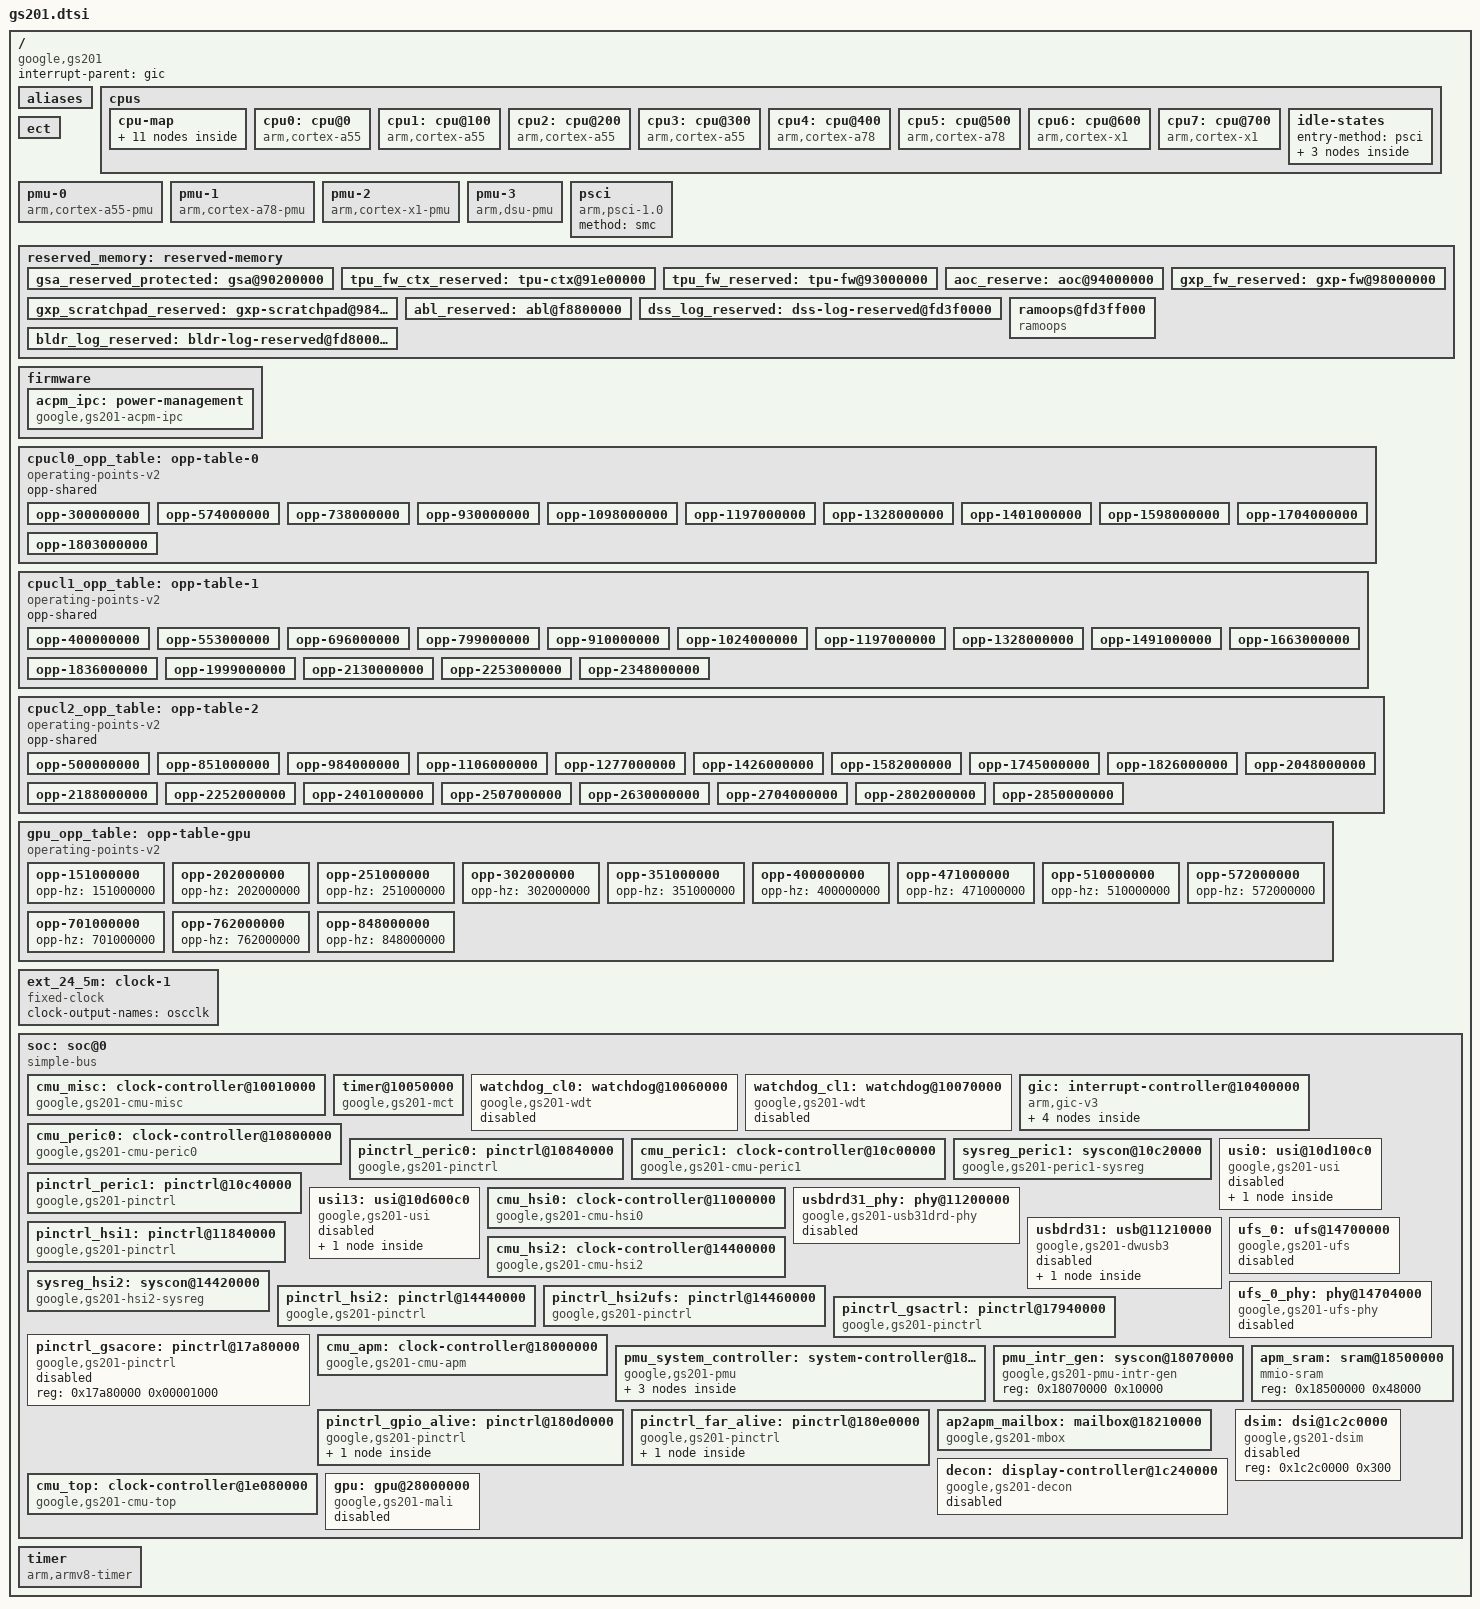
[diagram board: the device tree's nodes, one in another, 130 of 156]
// SPDX-License-Identifier: GPL-2.0-only
/*
 * GS201 SoC
 *
 * Copyright 2021-2023 Google LLC
 * Copyright 2023 Linaro Ltd - <peter.griffin@linaro.org>
 */

#include <dt-bindings/clock/google,gs201-acpm.h>
#include <dt-bindings/clock/google,gs201.h>
#include <dt-bindings/interrupt-controller/arm-gic.h>

/ {
	compatible = "google,gs201";
	#address-cells = <2>;
	#size-cells = <1>;

	interrupt-parent = <&gic>;

	aliases {
		pinctrl0 = &pinctrl_gpio_alive;
		pinctrl1 = &pinctrl_far_alive;
		pinctrl2 = &pinctrl_gsacore;
		pinctrl3 = &pinctrl_gsactrl;
		pinctrl4 = &pinctrl_peric0;
		pinctrl5 = &pinctrl_peric1;
		pinctrl6 = &pinctrl_hsi1;
		pinctrl7 = &pinctrl_hsi2;
		pinctrl8 = &pinctrl_hsi2ufs;
	};

	cpus {
		#address-cells = <1>;
		#size-cells = <0>;

		cpu-map {
			cluster0 {
				core0 {
					cpu = <&cpu0>;
				};

				core1 {
					cpu = <&cpu1>;
				};

				core2 {
					cpu = <&cpu2>;
				};

				core3 {
					cpu = <&cpu3>;
				};
			};

			cluster1 {
				core0 {
					cpu = <&cpu4>;
				};

				core1 {
					cpu = <&cpu5>;
				};
			};

			cluster2 {
				core0 {
					cpu = <&cpu6>;
				};

				core1 {
					cpu = <&cpu7>;
				};
			};
		};

		cpu0: cpu@0 {
			device_type = "cpu";
			compatible = "arm,cortex-a55";
			reg = <0x0000>;
			clocks = <&acpm_ipc GS201_CLK_ACPM_DVFS_CPUCL0>;
			enable-method = "psci";
			cpu-idle-states = <&ananke_cpu_sleep>;
			capacity-dmips-mhz = <250>;
			operating-points-v2 = <&cpucl0_opp_table>;
		};

		cpu1: cpu@100 {
			device_type = "cpu";
			compatible = "arm,cortex-a55";
			reg = <0x0100>;
			clocks = <&acpm_ipc GS201_CLK_ACPM_DVFS_CPUCL0>;
			enable-method = "psci";
			cpu-idle-states = <&ananke_cpu_sleep>;
			capacity-dmips-mhz = <250>;
			operating-points-v2 = <&cpucl0_opp_table>;
		};

		cpu2: cpu@200 {
			device_type = "cpu";
			compatible = "arm,cortex-a55";
			reg = <0x0200>;
			clocks = <&acpm_ipc GS201_CLK_ACPM_DVFS_CPUCL0>;
			enable-method = "psci";
			cpu-idle-states = <&ananke_cpu_sleep>;
			capacity-dmips-mhz = <250>;
			operating-points-v2 = <&cpucl0_opp_table>;
		};

		cpu3: cpu@300 {
			device_type = "cpu";
			compatible = "arm,cortex-a55";
			reg = <0x0300>;
			clocks = <&acpm_ipc GS201_CLK_ACPM_DVFS_CPUCL0>;
			enable-method = "psci";
			cpu-idle-states = <&ananke_cpu_sleep>;
			capacity-dmips-mhz = <250>;
			operating-points-v2 = <&cpucl0_opp_table>;
		};

		cpu4: cpu@400 {
			device_type = "cpu";
			compatible = "arm,cortex-a78";
			reg = <0x0400>;
			clocks = <&acpm_ipc GS201_CLK_ACPM_DVFS_CPUCL1>;
			enable-method = "psci";
			cpu-idle-states = <&hercules_cpu_sleep>;
			capacity-dmips-mhz = <927>;
			operating-points-v2 = <&cpucl1_opp_table>;
		};

		cpu5: cpu@500 {
			device_type = "cpu";
			compatible = "arm,cortex-a78";
			reg = <0x0500>;
			clocks = <&acpm_ipc GS201_CLK_ACPM_DVFS_CPUCL1>;
			enable-method = "psci";
			cpu-idle-states = <&hercules_cpu_sleep>;
			capacity-dmips-mhz = <927>;
			operating-points-v2 = <&cpucl1_opp_table>;
		};

		cpu6: cpu@600 {
			device_type = "cpu";
			compatible = "arm,cortex-x1";
			reg = <0x0600>;
			clocks = <&acpm_ipc GS201_CLK_ACPM_DVFS_CPUCL2>;
			enable-method = "psci";
			cpu-idle-states = <&hera_cpu_sleep>;
			capacity-dmips-mhz = <1024>;
			operating-points-v2 = <&cpucl2_opp_table>;
		};

		cpu7: cpu@700 {
			device_type = "cpu";
			compatible = "arm,cortex-x1";
			reg = <0x0700>;
			clocks = <&acpm_ipc GS201_CLK_ACPM_DVFS_CPUCL2>;
			enable-method = "psci";
			cpu-idle-states = <&hera_cpu_sleep>;
			capacity-dmips-mhz = <1024>;
			operating-points-v2 = <&cpucl2_opp_table>;
		};

		idle-states {
			entry-method = "psci";

			ananke_cpu_sleep: cpu-ananke-sleep {
				idle-state-name = "c2";
				compatible = "arm,idle-state";
				arm,psci-suspend-param = <0x0010000>;
				local-timer-stop;
				entry-latency-us = <70>;
				exit-latency-us = <160>;
				min-residency-us = <2000>;
			};

			hercules_cpu_sleep: cpu-hercules-sleep {
				idle-state-name = "c2";
				compatible = "arm,idle-state";
				arm,psci-suspend-param = <0x0010000>;
				local-timer-stop;
				entry-latency-us = <150>;
				exit-latency-us = <190>;
				min-residency-us = <2500>;
			};

			hera_cpu_sleep: cpu-hera-sleep {
				idle-state-name = "c2";
				compatible = "arm,idle-state";
				arm,psci-suspend-param = <0x0010000>;
				local-timer-stop;
				entry-latency-us = <235>;
				exit-latency-us = <220>;
				min-residency-us = <3500>;
			};
		};
	};

	/* ect node is required to be present by bootloader */
	ect {
	};

	pmu-0 {
		compatible = "arm,cortex-a55-pmu";
		interrupts = <GIC_PPI 7 IRQ_TYPE_LEVEL_HIGH &ppi_cluster0>;
	};

	pmu-1 {
		compatible = "arm,cortex-a78-pmu";
		interrupts = <GIC_PPI 7 IRQ_TYPE_LEVEL_HIGH &ppi_cluster1>;
	};

	pmu-2 {
		compatible = "arm,cortex-x1-pmu";
		interrupts = <GIC_PPI 7 IRQ_TYPE_LEVEL_HIGH &ppi_cluster2>;
	};

	pmu-3 {
		compatible = "arm,dsu-pmu";
		cpus = <&cpu0>, <&cpu1>, <&cpu2>, <&cpu3>,
		       <&cpu4>, <&cpu5>, <&cpu6>, <&cpu7>;
		interrupts = <GIC_SPI 152 IRQ_TYPE_LEVEL_HIGH 0>;
	};

	psci {
		compatible = "arm,psci-1.0";
		method = "smc";
	};

	/*
	 * The bootloader adds the secure world carve-outs (sec_dram, sec_pt
	 * and pkvm_guest_firmware) and debug_kinfo_reserved to this node at
	 * boot.
	 */
	reserved_memory: reserved-memory {
		#address-cells = <2>;
		#size-cells = <1>;
		ranges;

		gsa_reserved_protected: gsa@90200000 {
			reg = <0x0 0x90200000 0x400000>;
			no-map;
		};

		tpu_fw_ctx_reserved: tpu-ctx@91e00000 {
			reg = <0x0 0x91e00000 0x1200000>;
			no-map;
		};

		tpu_fw_reserved: tpu-fw@93000000 {
			reg = <0x0 0x93000000 0x1000000>;
			no-map;
		};

		aoc_reserve: aoc@94000000 {
			reg = <0x0 0x94000000 0x03000000>;
			no-map;
		};

		gxp_fw_reserved: gxp-fw@98000000 {
			reg = <0x0 0x98000000 0x400000>;
			no-map;
		};

		gxp_scratchpad_reserved: gxp-scratchpad@98400000 {
			reg = <0x0 0x98400000 0x100000>;
			no-map;
		};

		abl_reserved: abl@f8800000 {
			reg = <0x0 0xf8800000 0x02000000>;
			no-map;
		};

		dss_log_reserved: dss-log-reserved@fd3f0000 {
			reg = <0x0 0xfd3f0000 0x0000e000>;
			no-map;
		};

		ramoops@fd3ff000 {
			compatible = "ramoops";
			reg = <0x0 0xfd3ff000 0x400000>;
			console-size = <0x200000>;
			pmsg-size = <0x200000>;
		};

		bldr_log_reserved: bldr-log-reserved@fd800000 {
			reg = <0x0 0xfd800000 0x00100000>;
			no-map;
		};
	};

	firmware {
		acpm_ipc: power-management {
			compatible = "google,gs201-acpm-ipc";
			#clock-cells = <1>;
			mboxes = <&ap2apm_mailbox>;
			shmem = <&apm_sram>;
		};
	};

	/*
	 * CPU operating points from the ECT DVFS tables, up to the limits the
	 * Pixel kernels use. The firmware sets the voltages.
	 */
	cpucl0_opp_table: opp-table-0 {
		compatible = "operating-points-v2";
		opp-shared;

		opp-300000000 {
			opp-hz = /bits/ 64 <300000000>;
			clock-latency-ns = <500000>;
		};

		opp-574000000 {
			opp-hz = /bits/ 64 <574000000>;
			clock-latency-ns = <500000>;
		};

		opp-738000000 {
			opp-hz = /bits/ 64 <738000000>;
			clock-latency-ns = <500000>;
		};

		opp-930000000 {
			opp-hz = /bits/ 64 <930000000>;
			clock-latency-ns = <500000>;
		};

		opp-1098000000 {
			opp-hz = /bits/ 64 <1098000000>;
			clock-latency-ns = <500000>;
		};

		opp-1197000000 {
			opp-hz = /bits/ 64 <1197000000>;
			clock-latency-ns = <500000>;
		};

		opp-1328000000 {
			opp-hz = /bits/ 64 <1328000000>;
			clock-latency-ns = <500000>;
		};

		opp-1401000000 {
			opp-hz = /bits/ 64 <1401000000>;
			clock-latency-ns = <500000>;
		};

		opp-1598000000 {
			opp-hz = /bits/ 64 <1598000000>;
			clock-latency-ns = <500000>;
		};

		opp-1704000000 {
			opp-hz = /bits/ 64 <1704000000>;
			clock-latency-ns = <500000>;
		};

		opp-1803000000 {
			opp-hz = /bits/ 64 <1803000000>;
			clock-latency-ns = <500000>;
		};
	};

	cpucl1_opp_table: opp-table-1 {
		compatible = "operating-points-v2";
		opp-shared;

		opp-400000000 {
			opp-hz = /bits/ 64 <400000000>;
			clock-latency-ns = <500000>;
		};

		opp-553000000 {
			opp-hz = /bits/ 64 <553000000>;
			clock-latency-ns = <500000>;
		};

		opp-696000000 {
			opp-hz = /bits/ 64 <696000000>;
			clock-latency-ns = <500000>;
		};

		opp-799000000 {
			opp-hz = /bits/ 64 <799000000>;
			clock-latency-ns = <500000>;
		};

		opp-910000000 {
			opp-hz = /bits/ 64 <910000000>;
			clock-latency-ns = <500000>;
		};

		opp-1024000000 {
			opp-hz = /bits/ 64 <1024000000>;
			clock-latency-ns = <500000>;
		};

		opp-1197000000 {
			opp-hz = /bits/ 64 <1197000000>;
			clock-latency-ns = <500000>;
		};

		opp-1328000000 {
			opp-hz = /bits/ 64 <1328000000>;
			clock-latency-ns = <500000>;
		};

		opp-1491000000 {
			opp-hz = /bits/ 64 <1491000000>;
			clock-latency-ns = <500000>;
		};

		opp-1663000000 {
			opp-hz = /bits/ 64 <1663000000>;
			clock-latency-ns = <500000>;
		};

		opp-1836000000 {
			opp-hz = /bits/ 64 <1836000000>;
			clock-latency-ns = <500000>;
		};

		opp-1999000000 {
			opp-hz = /bits/ 64 <1999000000>;
			clock-latency-ns = <500000>;
		};

		opp-2130000000 {
			opp-hz = /bits/ 64 <2130000000>;
			clock-latency-ns = <500000>;
		};

		opp-2253000000 {
			opp-hz = /bits/ 64 <2253000000>;
			clock-latency-ns = <500000>;
		};

		opp-2348000000 {
			opp-hz = /bits/ 64 <2348000000>;
			clock-latency-ns = <500000>;
		};
	};

	cpucl2_opp_table: opp-table-2 {
		compatible = "operating-points-v2";
		opp-shared;

		opp-500000000 {
			opp-hz = /bits/ 64 <500000000>;
			clock-latency-ns = <500000>;
		};

		opp-851000000 {
			opp-hz = /bits/ 64 <851000000>;
			clock-latency-ns = <500000>;
		};

		opp-984000000 {
			opp-hz = /bits/ 64 <984000000>;
			clock-latency-ns = <500000>;
		};

		opp-1106000000 {
			opp-hz = /bits/ 64 <1106000000>;
			clock-latency-ns = <500000>;
		};

		opp-1277000000 {
			opp-hz = /bits/ 64 <1277000000>;
			clock-latency-ns = <500000>;
		};

		opp-1426000000 {
			opp-hz = /bits/ 64 <1426000000>;
			clock-latency-ns = <500000>;
		};

		opp-1582000000 {
			opp-hz = /bits/ 64 <1582000000>;
			clock-latency-ns = <500000>;
		};

		opp-1745000000 {
			opp-hz = /bits/ 64 <1745000000>;
			clock-latency-ns = <500000>;
		};

		opp-1826000000 {
			opp-hz = /bits/ 64 <1826000000>;
			clock-latency-ns = <500000>;
		};

		opp-2048000000 {
			opp-hz = /bits/ 64 <2048000000>;
			clock-latency-ns = <500000>;
		};

		opp-2188000000 {
			opp-hz = /bits/ 64 <2188000000>;
			clock-latency-ns = <500000>;
		};

		opp-2252000000 {
			opp-hz = /bits/ 64 <2252000000>;
			clock-latency-ns = <500000>;
		};

		opp-2401000000 {
			opp-hz = /bits/ 64 <2401000000>;
			clock-latency-ns = <500000>;
		};

		opp-2507000000 {
			opp-hz = /bits/ 64 <2507000000>;
			clock-latency-ns = <500000>;
		};

		opp-2630000000 {
			opp-hz = /bits/ 64 <2630000000>;
			clock-latency-ns = <500000>;
		};

		opp-2704000000 {
			opp-hz = /bits/ 64 <2704000000>;
			clock-latency-ns = <500000>;
		};

		opp-2802000000 {
			opp-hz = /bits/ 64 <2802000000>;
			clock-latency-ns = <500000>;
		};

		opp-2850000000 {
			opp-hz = /bits/ 64 <2850000000>;
			clock-latency-ns = <500000>;
		};
	};

	/*
	 * GPU operating points as shader clock rates. The ACPM "gpu" clock moves
	 * the L2 domain along with the shaders, and the firmware sets the
	 * voltages.
	 */
	gpu_opp_table: opp-table-gpu {
		compatible = "operating-points-v2";

		opp-151000000 {
			opp-hz = /bits/ 64 <151000000>;
		};

		opp-202000000 {
			opp-hz = /bits/ 64 <202000000>;
		};

		opp-251000000 {
			opp-hz = /bits/ 64 <251000000>;
		};

		opp-302000000 {
			opp-hz = /bits/ 64 <302000000>;
		};

		opp-351000000 {
			opp-hz = /bits/ 64 <351000000>;
		};

		opp-400000000 {
			opp-hz = /bits/ 64 <400000000>;
		};

		opp-471000000 {
			opp-hz = /bits/ 64 <471000000>;
		};

		opp-510000000 {
			opp-hz = /bits/ 64 <510000000>;
		};

		opp-572000000 {
			opp-hz = /bits/ 64 <572000000>;
		};

		opp-701000000 {
			opp-hz = /bits/ 64 <701000000>;
		};

		opp-762000000 {
			opp-hz = /bits/ 64 <762000000>;
		};

		opp-848000000 {
			opp-hz = /bits/ 64 <848000000>;
		};
	};

	ext_24_5m: clock-1 {
		compatible = "fixed-clock";
		#clock-cells = <0>;
		clock-output-names = "oscclk";
	};

	soc: soc@0 {
		compatible = "simple-bus";
		#address-cells = <1>;
		#size-cells = <1>;
		ranges = <0x0 0x0 0x0 0x40000000>;

		cmu_misc: clock-controller@10010000 {
			compatible = "google,gs201-cmu-misc";
			reg = <0x10010000 0x10000>;
			#clock-cells = <1>;
			clocks = <&cmu_top CLK_DOUT_CMU_MISC_NOC>,
				 <&cmu_top CLK_DOUT_CMU_MISC_SSS>;
			clock-names = "bus", "sss";
		};

		timer@10050000 {
			compatible = "google,gs201-mct",
				     "samsung,exynos4210-mct";
			reg = <0x10050000 0x800>;
			clocks = <&ext_24_5m>, <&cmu_misc CLK_GOUT_MISC_MCT_PCLK>;
			clock-names = "fin_pll", "mct";
			interrupts = <GIC_SPI 785 IRQ_TYPE_LEVEL_HIGH 0>,
				     <GIC_SPI 786 IRQ_TYPE_LEVEL_HIGH 0>,
				     <GIC_SPI 787 IRQ_TYPE_LEVEL_HIGH 0>,
				     <GIC_SPI 788 IRQ_TYPE_LEVEL_HIGH 0>,
				     <GIC_SPI 789 IRQ_TYPE_LEVEL_HIGH 0>,
				     <GIC_SPI 790 IRQ_TYPE_LEVEL_HIGH 0>,
				     <GIC_SPI 791 IRQ_TYPE_LEVEL_HIGH 0>,
				     <GIC_SPI 792 IRQ_TYPE_LEVEL_HIGH 0>,
				     <GIC_SPI 793 IRQ_TYPE_LEVEL_HIGH 0>,
				     <GIC_SPI 794 IRQ_TYPE_LEVEL_HIGH 0>,
				     <GIC_SPI 795 IRQ_TYPE_LEVEL_HIGH 0>,
				     <GIC_SPI 796 IRQ_TYPE_LEVEL_HIGH 0>;
		};

		watchdog_cl0: watchdog@10060000 {
			compatible = "google,gs201-wdt", "google,gs101-wdt";
			reg = <0x10060000 0x100>;
			clocks = <&cmu_misc CLK_GOUT_MISC_WDT_CLUSTER0_PCLK>,
				 <&ext_24_5m>;
			clock-names = "watchdog", "watchdog_src";
			interrupts = <GIC_SPI 797 IRQ_TYPE_LEVEL_HIGH 0>;
			samsung,syscon-phandle = <&pmu_system_controller>;
			samsung,cluster-index = <0>;

			status = "disabled";
		};

		watchdog_cl1: watchdog@10070000 {
			compatible = "google,gs201-wdt", "google,gs101-wdt";
			reg = <0x10070000 0x100>;
			clocks = <&cmu_misc CLK_GOUT_MISC_WDT_CLUSTER1_PCLK>,
				 <&ext_24_5m>;
			clock-names = "watchdog", "watchdog_src";
			interrupts = <GIC_SPI 798 IRQ_TYPE_LEVEL_HIGH 0>;
			samsung,syscon-phandle = <&pmu_system_controller>;
			samsung,cluster-index = <1>;

			status = "disabled";
		};

		gic: interrupt-controller@10400000 {
			compatible = "arm,gic-v3";
			#address-cells = <0>;
			#interrupt-cells = <4>;
			interrupt-controller;
			reg = <0x10400000 0x10000>, /* GICD */
			      <0x10440000 0x100000>;/* GICR * 8 */
			interrupts = <GIC_PPI 9 IRQ_TYPE_LEVEL_HIGH 0>;

			ppi-partitions {
				ppi_cluster0: interrupt-partition-0 {
					affinity = <&cpu0 &cpu1 &cpu2 &cpu3>;
				};

				ppi_cluster1: interrupt-partition-1 {
					affinity = <&cpu4 &cpu5>;
				};

				ppi_cluster2: interrupt-partition-2 {
					affinity = <&cpu6 &cpu7>;
				};
			};
		};

		cmu_peric0: clock-controller@10800000 {
			compatible = "google,gs201-cmu-peric0";
			reg = <0x10800000 0x10000>;
			#clock-cells = <1>;
			clocks = <&ext_24_5m>,
				 <&cmu_top CLK_DOUT_CMU_PERIC0_NOC>,
				 <&cmu_top CLK_DOUT_CMU_PERIC0_IP>;
			clock-names = "oscclk", "bus", "ip";
		};

		pinctrl_peric0: pinctrl@10840000 {
			compatible = "google,gs201-pinctrl";
			reg = <0x10840000 0x00001000>;
			clocks = <&cmu_peric0 CLK_GOUT_PERIC0_GPIO_PERIC0_PCLK>;
			clock-names = "pclk";
			interrupts = <GIC_SPI 664 IRQ_TYPE_LEVEL_HIGH 0>;
		};

		cmu_peric1: clock-controller@10c00000 {
			compatible = "google,gs201-cmu-peric1";
			reg = <0x10c00000 0x10000>;
			#clock-cells = <1>;
			clocks = <&ext_24_5m>,
				 <&cmu_top CLK_DOUT_CMU_PERIC1_NOC>,
				 <&cmu_top CLK_DOUT_CMU_PERIC1_IP>;
			clock-names = "oscclk", "bus", "ip";
		};

		sysreg_peric1: syscon@10c20000 {
			compatible = "google,gs201-peric1-sysreg", "syscon";
			reg = <0x10c20000 0x10000>;
			clocks = <&cmu_peric1 CLK_GOUT_PERIC1_SYSREG_PERIC1_PCLK>;
		};

		pinctrl_peric1: pinctrl@10c40000 {
			compatible = "google,gs201-pinctrl";
			reg = <0x10c40000 0x00001000>;
			clocks = <&cmu_peric1 CLK_GOUT_PERIC1_GPIO_PERIC1_PCLK>;
			clock-names = "pclk";
			interrupts = <GIC_SPI 683 IRQ_TYPE_LEVEL_HIGH 0>;
		};

		usi0: usi@10d100c0 {
			compatible = "google,gs201-usi", "samsung,exynos850-usi";
			reg = <0x10d100c0 0x20>;
			ranges;
			#address-cells = <1>;
			#size-cells = <1>;
			clocks = <&cmu_peric1 CLK_GOUT_PERIC1_USI0_USI_PCLK>,
				 <&cmu_peric1 CLK_GOUT_PERIC1_USI0_USI_IPCLK>;
			clock-names = "pclk", "ipclk";
			samsung,sysreg = <&sysreg_peric1 0x1000>;

			status = "disabled";

			spi_0: spi@10d10000 {
				compatible = "google,gs201-spi", "google,gs101-spi";
				reg = <0x10d10000 0x30>;
				#address-cells = <1>;
				#size-cells = <0>;
				clocks = <&cmu_peric1 CLK_GOUT_PERIC1_USI0_USI_PCLK>,
					 <&cmu_peric1 CLK_GOUT_PERIC1_USI0_USI_IPCLK>;
				clock-names = "spi", "spi_busclk0";
				interrupts = <GIC_SPI 690 IRQ_TYPE_LEVEL_HIGH 0>;
				pinctrl-0 = <&spi0_bus>;
				pinctrl-names = "default";

				status = "disabled";
			};
		};

		usi13: usi@10d600c0 {
			compatible = "google,gs201-usi", "samsung,exynos850-usi";
			reg = <0x10d600c0 0x20>;
			ranges;
			#address-cells = <1>;
			#size-cells = <1>;
			clocks = <&cmu_peric1 CLK_GOUT_PERIC1_USI13_USI_PCLK>,
				 <&cmu_peric1 CLK_GOUT_PERIC1_USI13_USI_IPCLK>;
			clock-names = "pclk", "ipclk";
			samsung,sysreg = <&sysreg_peric1 0x1014>;

			status = "disabled";

			hsi2c_13: i2c@10d60000 {
				compatible = "google,gs201-hsi2c",
					     "samsung,exynosautov9-hsi2c";
				reg = <0x10d60000 0xc0>;
				#address-cells = <1>;
				#size-cells = <0>;
				clocks = <&cmu_peric1 CLK_GOUT_PERIC1_USI13_USI_IPCLK>,
					 <&cmu_peric1 CLK_GOUT_PERIC1_USI13_USI_PCLK>;
				clock-names = "hsi2c", "hsi2c_pclk";
				interrupts = <GIC_SPI 695 IRQ_TYPE_LEVEL_HIGH 0>;
				pinctrl-0 = <&hsi2c13_bus>;
				pinctrl-names = "default";

				status = "disabled";
			};
		};

		cmu_hsi0: clock-controller@11000000 {
			compatible = "google,gs201-cmu-hsi0";
			reg = <0x11000000 0x10000>;
			#clock-cells = <1>;
			clocks = <&ext_24_5m>,
				 <&cmu_top CLK_DOUT_CMU_HSI0_NOC>,
				 <&cmu_top CLK_DOUT_CMU_HSI0_DPGTC>,
				 <&cmu_top CLK_DOUT_CMU_HSI0_USB31DRD>,
				 <&cmu_top CLK_DOUT_CMU_HSI0_USBDPDBG>;
			clock-names = "oscclk", "bus", "dpgtc", "usb31drd",
				      "usbdpdbg";
		};

		usbdrd31_phy: phy@11200000 {
			compatible = "google,gs201-usb31drd-phy",
				     "google,gs101-usb31drd-phy";
			reg = <0x11200000 0x0200>,
			      <0x11100000 0x0800>,
			      <0x110f0000 0x2800>;
			reg-names = "phy", "pcs", "pma";
			clocks = <&cmu_hsi0 CLK_GOUT_HSI0_USB31DRD_ACLK_PHYCTRL>,
				 <&cmu_hsi0 CLK_GOUT_HSI0_USB31DRD_I_USB20_PHY_REFCLK_26>,
				 <&cmu_hsi0 CLK_GOUT_HSI0_UASC_HSI0_CTRL_ACLK>,
				 <&cmu_hsi0 CLK_GOUT_HSI0_UASC_HSI0_CTRL_PCLK>,
				 <&cmu_hsi0 CLK_GOUT_HSI0_USB31DRD_I_USBDPPHY_SCL_APB_PCLK>;
			clock-names = "phy", "ref", "ctrl_aclk", "ctrl_pclk", "scl_pclk";
			#phy-cells = <1>;
			samsung,pmu-syscon = <&pmu_system_controller>;

			status = "disabled";
		};

		usbdrd31: usb@11210000 {
			compatible = "google,gs201-dwusb3", "google,gs101-dwusb3";
			ranges = <0x0 0x11210000 0x10000>;
			clocks = <&cmu_hsi0 CLK_GOUT_HSI0_USB31DRD_BUS_CLK_EARLY>,
				 <&cmu_hsi0 CLK_GOUT_HSI0_USB31DRD_I_USB31DRD_SUSPEND_CLK_26>,
				 <&cmu_hsi0 CLK_GOUT_HSI0_UASC_HSI0_LINK_ACLK>,
				 <&cmu_hsi0 CLK_GOUT_HSI0_UASC_HSI0_LINK_PCLK>;
			clock-names = "bus_early", "susp_clk", "link_aclk", "link_pclk";
			#address-cells = <1>;
			#size-cells = <1>;

			status = "disabled";

			usbdrd31_dwc3: usb@0 {
				compatible = "snps,dwc3";
				reg = <0x0 0x10000>;
				clocks = <&cmu_hsi0 CLK_GOUT_HSI0_USB31DRD_I_USB31DRD_REF_CLK_40>;
				clock-names = "ref";
				interrupts = <GIC_SPI 379 IRQ_TYPE_LEVEL_HIGH 0>;
				phys = <&usbdrd31_phy 0>, <&usbdrd31_phy 1>;
				phy-names = "usb2-phy", "usb3-phy";
				snps,has-lpm-erratum;
				snps,dis_u2_susphy_quirk;
				snps,dis_u3_susphy_quirk;

				status = "disabled";
			};
		};

		pinctrl_hsi1: pinctrl@11840000 {
			compatible = "google,gs201-pinctrl";
			reg = <0x11840000 0x00001000>;
			/* TODO: update once support for this CMU exists */
			clocks = <0>;
			clock-names = "pclk";
			interrupts = <GIC_SPI 387 IRQ_TYPE_LEVEL_HIGH 0>;
		};

		cmu_hsi2: clock-controller@14400000 {
			compatible = "google,gs201-cmu-hsi2";
			reg = <0x14400000 0x10000>;
			#clock-cells = <1>;
			clocks = <&ext_24_5m>,
				 <&cmu_top CLK_DOUT_CMU_HSI2_NOC>,
				 <&cmu_top CLK_DOUT_CMU_HSI2_PCIE>,
				 <&cmu_top CLK_DOUT_CMU_HSI2_UFS_EMBD>,
				 <&cmu_top CLK_DOUT_CMU_HSI2_MMC_CARD>;
			clock-names = "oscclk", "bus", "pcie", "ufs", "mmc";
		};

		sysreg_hsi2: syscon@14420000 {
			compatible = "google,gs201-hsi2-sysreg", "syscon";
			reg = <0x14420000 0x10000>;
			clocks = <&cmu_hsi2 CLK_GOUT_HSI2_SYSREG_HSI2_PCLK>;
		};

		pinctrl_hsi2: pinctrl@14440000 {
			compatible = "google,gs201-pinctrl";
			reg = <0x14440000 0x00001000>;
			clocks = <&cmu_hsi2 CLK_GOUT_HSI2_GPIO_HSI2_PCLK>;
			clock-names = "pclk";
			interrupts = <GIC_SPI 421 IRQ_TYPE_LEVEL_HIGH 0>;
		};

		pinctrl_hsi2ufs: pinctrl@14460000 {
			compatible = "google,gs201-pinctrl";
			reg = <0x14460000 0x00001000>;
			clocks = <&cmu_hsi2 CLK_GOUT_HSI2_GPIO_HSI2UFS_PCLK>;
			clock-names = "pclk";
			interrupts = <GIC_SPI 422 IRQ_TYPE_LEVEL_HIGH 0>;
		};

		ufs_0: ufs@14700000 {
			compatible = "google,gs201-ufs";
			reg = <0x14700000 0x200>,
			      <0x14701100 0x200>,
			      <0x14780000 0xa000>,
			      <0x14600000 0x100>;
			reg-names = "hci", "vs_hci", "unipro", "ufsp";
			interrupts = <GIC_SPI 453 IRQ_TYPE_LEVEL_HIGH 0>;
			clocks = <&cmu_hsi2 CLK_GOUT_HSI2_UFS_EMBD_I_ACLK>,
				 <&cmu_hsi2 CLK_GOUT_HSI2_UFS_EMBD_I_CLK_UNIPRO>,
				 <&cmu_hsi2 CLK_GOUT_HSI2_UFS_EMBD_I_FMP_CLK>,
				 <&cmu_hsi2 CLK_GOUT_HSI2_QE_UFS_EMBD_HSI2_ACLK>,
				 <&cmu_hsi2 CLK_GOUT_HSI2_QE_UFS_EMBD_HSI2_PCLK>,
				 <&cmu_hsi2 CLK_GOUT_HSI2_SYSREG_HSI2_PCLK>;
			clock-names = "core_clk", "sclk_unipro_main", "fmp",
				      "aclk", "pclk", "sysreg";
			dma-coherent;
			freq-table-hz = <0 0>, <0 0>, <0 0>, <0 0>, <0 0>, <0 0>;
			pinctrl-0 = <&ufs_rst_n &ufs_refclk_out>;
			pinctrl-names = "default";
			phys = <&ufs_0_phy>;
			phy-names = "ufs-phy";
			samsung,sysreg = <&sysreg_hsi2 0x710>;

			status = "disabled";
		};

		ufs_0_phy: phy@14704000 {
			compatible = "google,gs201-ufs-phy";
			reg = <0x14704000 0x3000>;
			reg-names = "phy-pma";
			samsung,pmu-syscon = <&pmu_system_controller>;
			#phy-cells = <0>;
			clocks = <&ext_24_5m>;
			clock-names = "ref_clk";

			status = "disabled";
		};

		pinctrl_gsactrl: pinctrl@17940000 {
			compatible = "google,gs201-pinctrl";
			reg = <0x17940000 0x00001000>;
			/* TODO: update once support for this CMU exists */
			clocks = <0>;
			clock-names = "pclk";
		};

		pinctrl_gsacore: pinctrl@17a80000 {
			compatible = "google,gs201-pinctrl";
			reg = <0x17a80000 0x00001000>;

			status = "disabled";
		};

		cmu_apm: clock-controller@18000000 {
			compatible = "google,gs201-cmu-apm";
			reg = <0x18000000 0x10000>;
			#clock-cells = <1>;
			clocks = <&ext_24_5m>;
			clock-names = "oscclk";
		};

		pmu_system_controller: system-controller@18060000 {
			compatible = "google,gs201-pmu", "google,gs101-pmu";
			reg = <0x18060000 0x10000>;
			google,pmu-intr-gen-syscon = <&pmu_intr_gen>;

			poweroff: syscon-poweroff {
				compatible = "syscon-poweroff";
				offset = <0x3e9c>; /* PAD_CTRL_PWR_HOLD */
				mask = <0x00000100>;
				value = <0x0>;
			};

			reboot: syscon-reboot {
				compatible = "google,gs201-reboot",
					     "google,gs101-reboot";
			};

			reboot-mode {
				compatible = "syscon-reboot-mode";
				offset = <0x0810>; /* EXYNOS_PMU_SYSIP_DAT0 */
				mode-bootloader = <0xfc>;
				mode-charge = <0x0a>;
				mode-dm-verity-device-corrupted = <0x50>;
				mode-fastboot = <0xfa>;
				mode-reboot-ab-update = <0x52>;
				mode-recovery = <0xff>;
				mode-rescue = <0xf9>;
				mode-shutdown-thermal = <0x51>;
				mode-shutdown-thermal-battery = <0x51>;
			};
		};

		pmu_intr_gen: syscon@18070000 {
			compatible = "google,gs201-pmu-intr-gen",
				     "google,gs101-pmu-intr-gen", "syscon";
			reg = <0x18070000 0x10000>;
		};

		pinctrl_gpio_alive: pinctrl@180d0000 {
			compatible = "google,gs201-pinctrl";
			reg = <0x180d0000 0x00001000>;
			clocks = <&cmu_apm CLK_GOUT_APM_APBIF_GPIO_ALIVE_PCLK>;
			clock-names = "pclk";

			wakeup-interrupt-controller {
				compatible = "google,gs201-wakeup-eint",
					     "google,gs101-wakeup-eint",
					     "samsung,exynos850-wakeup-eint",
					     "samsung,exynos7-wakeup-eint";
			};
		};

		pinctrl_far_alive: pinctrl@180e0000 {
			compatible = "google,gs201-pinctrl";
			reg = <0x180e0000 0x00001000>;
			clocks = <&cmu_apm CLK_GOUT_APM_APBIF_GPIO_FAR_ALIVE_PCLK>;
			clock-names = "pclk";

			wakeup-interrupt-controller {
				compatible = "google,gs201-wakeup-eint",
					     "google,gs101-wakeup-eint",
					     "samsung,exynos850-wakeup-eint",
					     "samsung,exynos7-wakeup-eint";
			};
		};

		ap2apm_mailbox: mailbox@18210000 {
			compatible = "google,gs201-mbox", "google,gs101-mbox";
			reg = <0x18210000 0x1000>;
			clocks = <&cmu_apm CLK_GOUT_APM_MAILBOX_APM_AP_PCLK>;
			clock-names = "pclk";
			interrupts = <GIC_SPI 78 IRQ_TYPE_LEVEL_HIGH 0>;
			#mbox-cells = <0>;
		};

		apm_sram: sram@18500000 {
			compatible = "mmio-sram";
			reg = <0x18500000 0x48000>;
			#address-cells = <1>;
			#size-cells = <1>;
			ranges = <0x0 0x18500000 0x48000>;
		};

		decon: display-controller@1c240000 {
			compatible = "google,gs201-decon";
			reg = <0x1c240000 0x1000>, <0x1c0b0000 0x6000>;
			reg-names = "decon", "dma";
			interrupts = <GIC_SPI 240 IRQ_TYPE_LEVEL_HIGH 0>;
			interrupt-names = "frame-done";

			status = "disabled";
		};

		dsim: dsi@1c2c0000 {
			compatible = "google,gs201-dsim";
			reg = <0x1c2c0000 0x300>;
			#address-cells = <1>;
			#size-cells = <0>;

			status = "disabled";
		};

		cmu_top: clock-controller@1e080000 {
			compatible = "google,gs201-cmu-top";
			reg = <0x1e080000 0x10000>;
			#clock-cells = <1>;
			clocks = <&ext_24_5m>;
			clock-names = "oscclk";
		};

		/*
		 * The bootloader leaves the G3D power domains on. Switching them
		 * needs secure PMU accesses that the Exynos power domain driver
		 * does not make yet.
		 */
		gpu: gpu@28000000 {
			compatible = "google,gs201-mali", "arm,mali-valhall-csf";
			reg = <0x28000000 0x480000>;
			interrupts = <GIC_SPI 329 IRQ_TYPE_LEVEL_HIGH 0>,
				     <GIC_SPI 330 IRQ_TYPE_LEVEL_HIGH 0>,
				     <GIC_SPI 328 IRQ_TYPE_LEVEL_HIGH 0>;
			interrupt-names = "job", "mmu", "gpu";
			clocks = <&acpm_ipc GS201_CLK_ACPM_GPU>;
			clock-names = "core";
			operating-points-v2 = <&gpu_opp_table>;

			status = "disabled";
		};
	};

	timer {
		compatible = "arm,armv8-timer";
		interrupts =
		   <GIC_PPI 13 (GIC_CPU_MASK_SIMPLE(8) | IRQ_TYPE_LEVEL_LOW) 0>,
		   <GIC_PPI 14 (GIC_CPU_MASK_SIMPLE(8) | IRQ_TYPE_LEVEL_LOW) 0>,
		   <GIC_PPI 11 (GIC_CPU_MASK_SIMPLE(8) | IRQ_TYPE_LEVEL_LOW) 0>,
		   <GIC_PPI 10 (GIC_CPU_MASK_SIMPLE(8) | IRQ_TYPE_LEVEL_LOW) 0>;
	};
};

#include "gs201-pinctrl.dtsi"
